AUTOSAR XML (schema 4-2-2)
package /Acme/Types
  base type Word: category=FIXED_LENGTH, base-type-size=16, base-type-encoding=NONE, native-declaration=uint16
  impl type RawA: category=VALUE, base-type=Word
  impl type RawB: category=VALUE, base-type=Word
  app type Pressure: category=VALUE, unit=bar
  app type Torque: category=VALUE, unit=Nm
  unit Bar: display-name=bar
  unit Newton: display-name=Nm
package /Acme/Mappings
  data type mapping set PressureMaps: data-type-map{application-data-type=Pressure, implementation-data-type=RawA}
  data type mapping set TorqueMaps
    data-type-maps:
      application-data-type=Torque, implementation-data-type=RawB
      application-data-type=Pressure, implementation-data-type=RawA
package /Acme/Interfaces
  sender receiver interface IPressure
    data pressure: type=Pressure
  sender receiver interface ITorque
    data torque: type=Torque
package /Acme/Components
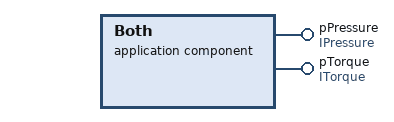
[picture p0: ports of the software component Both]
  application sw component type Both
    provide port pPressure: provided-interface=IPressure
    provide port pTorque: provided-interface=ITorque
    behavior BothBehavior: data-type-mapping=[TorqueMaps, PressureMaps], handle-termination-and-restart=NO-SUPPORT
package /Acme/Sinks
  application sw component type TorqueOnly
    require port rTorque: required-interface=ITorque
    behavior TorqueOnlyBehavior: data-type-mapping=TorqueMaps, handle-termination-and-restart=NO-SUPPORT
package /Acme/Hierarchy
  composition sw component type Root
    component both: type=Both
    component torqueOnly: type=TorqueOnly
